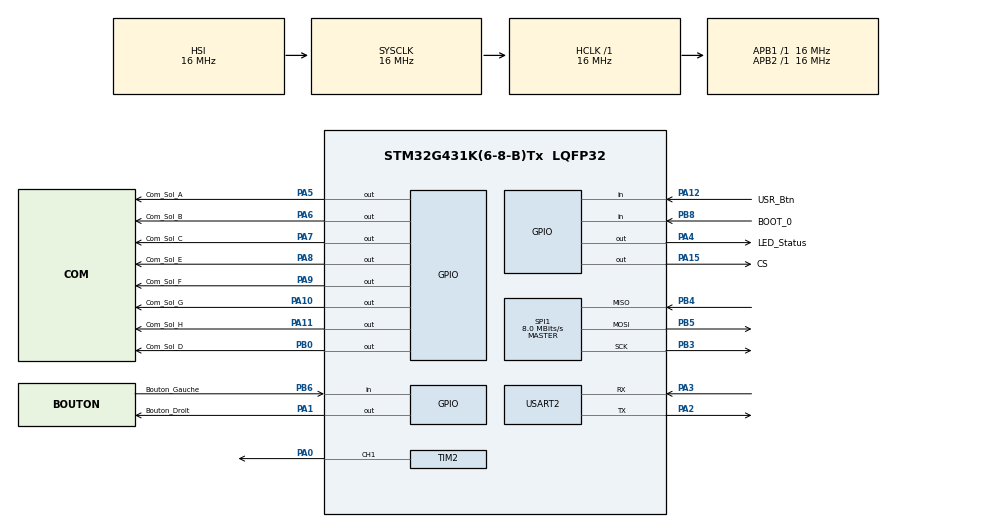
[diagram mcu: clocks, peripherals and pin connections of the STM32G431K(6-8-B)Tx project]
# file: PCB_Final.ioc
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Dma.Request0=TIM2_CH1
Dma.TIM2_CH1.0.Direction=DMA_MEMORY_TO_PERIPH
Dma.TIM2_CH1.0.EventEnable=DISABLE
Dma.TIM2_CH1.0.Instance=DMA1_Channel1
Dma.TIM2_CH1.0.MemDataAlignment=DMA_MDATAALIGN_WORD
Dma.TIM2_CH1.0.MemInc=DMA_MINC_ENABLE
Dma.TIM2_CH1.0.Mode=DMA_CIRCULAR
Dma.TIM2_CH1.0.PeriphDataAlignment=DMA_PDATAALIGN_WORD
Dma.TIM2_CH1.0.PeriphInc=DMA_PINC_DISABLE
Dma.TIM2_CH1.0.Polarity=HAL_DMAMUX_REQ_GEN_RISING
Dma.TIM2_CH1.0.Priority=DMA_PRIORITY_LOW
Dma.TIM2_CH1.0.RequestNumber=1
Dma.TIM2_CH1.0.SignalID=NONE
Dma.TIM2_CH1.0.SyncEnable=DISABLE
Dma.TIM2_CH1.0.SyncPolarity=HAL_DMAMUX_SYNC_NO_EVENT
Dma.TIM2_CH1.0.SyncRequestNumber=1
Dma.TIM2_CH1.0.SyncSignalID=NONE
Mcu.Family=STM32G4
Mcu.Name=STM32G431K(6-8-B)Tx
Mcu.Package=LQFP32
NVIC.DMA1_Channel1_IRQn=true\:0\:0\:false\:false\:true\:false\:true\:true
NVIC.PriorityGroup=NVIC_PRIORITYGROUP_4
NVIC.TIM2_IRQn=true\:0\:0\:false\:false\:true\:true\:true\:true
PA0.Signal=S_TIM2_CH1
PA1.GPIO_Label=Bouton_Droit
PA1.Signal=GPIO_Output
PA10.GPIO_Label=Com_Sol_G
PA10.Signal=GPIO_Output
PA11.GPIO_Label=Com_Sol_H
PA11.Signal=GPIO_Output
PA12.GPIO_Label=USR_Btn
PA12.Signal=GPIO_Input
PA13.Signal=SYS_JTMS-SWDIO
PA14.Signal=SYS_JTCK-SWCLK
PA15.GPIO_Label=CS
PA15.Signal=GPIO_Output
PA2.Mode=Asynchronous
PA2.Signal=USART2_TX
PA3.Mode=Asynchronous
PA3.Signal=USART2_RX
PA4.GPIO_Label=LED_Status
PA4.Signal=GPIO_Output
PA5.GPIO_Label=Com_Sol_A
PA5.Signal=GPIO_Output
PA6.GPIO_Label=Com_Sol_B
PA6.Signal=GPIO_Output
PA7.GPIO_Label=Com_Sol_C
PA7.Signal=GPIO_Output
PA8.GPIO_Label=Com_Sol_E
PA8.Signal=GPIO_Output
PA9.GPIO_Label=Com_Sol_F
PA9.Signal=GPIO_Output
PB0.GPIO_Label=Com_Sol_D
PB0.Signal=GPIO_Output
PB3.Mode=Full_Duplex_Master
PB3.Signal=SPI1_SCK
PB4.Mode=Full_Duplex_Master
PB4.Signal=SPI1_MISO
PB5.Mode=Full_Duplex_Master
PB5.Signal=SPI1_MOSI
PB6.GPIO_Label=Bouton_Gauche
PB6.Signal=GPIO_Input
PB8-BOOT0.GPIO_Label=BOOT_0
PB8-BOOT0.Signal=GPIO_Input
ProjectManager.HeapSize=0x200
ProjectManager.StackSize=0x400
ProjectManager.TargetToolchain=STM32CubeIDE
RCC.AHBFreq_Value=16000000
RCC.APB1Freq_Value=16000000
RCC.APB1TimFreq_Value=16000000
RCC.APB2Freq_Value=16000000
RCC.APB2TimFreq_Value=16000000
RCC.CortexFreq_Value=16000000
RCC.EXTERNAL_CLOCK_VALUE=12288000
RCC.HCLKFreq_Value=16000000
RCC.HSE_VALUE=8000000
RCC.HSI48_VALUE=48000000
RCC.HSI_VALUE=16000000
RCC.LSE_VALUE=32768
RCC.SYSCLKFreq_VALUE=16000000
RCC.USBFreq_Value=64000000
RCC.VCOOutputFreq_Value=128000000
SH.S_TIM2_CH1.0=TIM2_CH1,PWM Generation1 CH1
SPI1.CalculateBaudRate=8.0 MBits/s
SPI1.Direction=SPI_DIRECTION_2LINES
SPI1.Mode=SPI_MODE_MASTER
SPI1.VirtualType=VM_MASTER
TIM2.Channel-PWM\ Generation1\ CH1=TIM_CHANNEL_1
USART2.VirtualMode-Asynchronous=VM_ASYNC
VP_SYS_VS_DBSignals.Mode=DisableDeadBatterySignals
board=custom

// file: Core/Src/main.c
/* USER CODE BEGIN Header */
/**
  ******************************************************************************
  * @file           : main.c
  * @brief          : Main program body
  ******************************************************************************
  * @attention
  *
  * Copyright (c) 2026 STMicroelectronics.
  * All rights reserved.
  *
  * This software is licensed under terms that can be found in the LICENSE file
  * in the root directory of this software component.
  * If no LICENSE file comes with this software, it is provided AS-IS.
  *
  ******************************************************************************
  */
/* USER CODE END Header */
#include "main.h"

SPI_HandleTypeDef hspi1;

TIM_HandleTypeDef htim2;
DMA_HandleTypeDef hdma_tim2_ch1;

UART_HandleTypeDef huart2;

void SystemClock_Config(void);
static void MX_GPIO_Init(void);
static void MX_DMA_Init(void);
static void MX_USART2_UART_Init(void);
static void MX_TIM2_Init(void);
static void MX_SPI1_Init(void);

int main(void)
{

  /* MCU Configuration--------------------------------------------------------*/

  /* Reset of all peripherals, Initializes the Flash interface and the Systick. */
  HAL_Init();

  /* Configure the system clock */
  SystemClock_Config();

  /* Initialize all configured peripherals */
  MX_GPIO_Init();
  MX_DMA_Init();
  MX_USART2_UART_Init();
  MX_TIM2_Init();
  MX_SPI1_Init();
  /* USER CODE BEGIN 2 */
uint32_t tableau[24] = {0};	// timings 1 et 0

HAL_TIM_PWM_Start_DMA(&htim2, TIM_CHANNEL_1, tableau, 24);
  /* USER CODE END 2 */

  /* Infinite loop */
  while (1)
  {

  }
}

void SystemClock_Config(void)
{
  RCC_OscInitTypeDef RCC_OscInitStruct = {0};
  RCC_ClkInitTypeDef RCC_ClkInitStruct = {0};

  /** Configure the main internal regulator output voltage
  */
  HAL_PWREx_ControlVoltageScaling(PWR_REGULATOR_VOLTAGE_SCALE1);

  /** Initializes the RCC Oscillators according to the specified parameters
  * in the RCC_OscInitTypeDef structure.
  */
  RCC_OscInitStruct.OscillatorType = RCC_OSCILLATORTYPE_HSI;
  RCC_OscInitStruct.HSIState = RCC_HSI_ON;
  RCC_OscInitStruct.HSICalibrationValue = RCC_HSICALIBRATION_DEFAULT;
  RCC_OscInitStruct.PLL.PLLState = RCC_PLL_NONE;
  if (HAL_RCC_OscConfig(&RCC_OscInitStruct) != HAL_OK)
  {
    Error_Handler();
  }

  /** Initializes the CPU, AHB and APB buses clocks
  */
  RCC_ClkInitStruct.ClockType = RCC_CLOCKTYPE_HCLK|RCC_CLOCKTYPE_SYSCLK
                              |RCC_CLOCKTYPE_PCLK1|RCC_CLOCKTYPE_PCLK2;
  RCC_ClkInitStruct.SYSCLKSource = RCC_SYSCLKSOURCE_HSI;
  RCC_ClkInitStruct.AHBCLKDivider = RCC_SYSCLK_DIV1;
  RCC_ClkInitStruct.APB1CLKDivider = RCC_HCLK_DIV1;
  RCC_ClkInitStruct.APB2CLKDivider = RCC_HCLK_DIV1;

  if (HAL_RCC_ClockConfig(&RCC_ClkInitStruct, FLASH_LATENCY_0) != HAL_OK)
  {
    Error_Handler();
  }
}

static void MX_SPI1_Init(void)
{

  /* SPI1 parameter configuration*/
  hspi1.Instance = SPI1;
  hspi1.Init.Mode = SPI_MODE_MASTER;
  hspi1.Init.Direction = SPI_DIRECTION_2LINES;
  hspi1.Init.DataSize = SPI_DATASIZE_4BIT;
  hspi1.Init.CLKPolarity = SPI_POLARITY_LOW;
  hspi1.Init.CLKPhase = SPI_PHASE_1EDGE;
  hspi1.Init.NSS = SPI_NSS_SOFT;
  hspi1.Init.BaudRatePrescaler = SPI_BAUDRATEPRESCALER_2;
  hspi1.Init.FirstBit = SPI_FIRSTBIT_MSB;
  hspi1.Init.TIMode = SPI_TIMODE_DISABLE;
  hspi1.Init.CRCCalculation = SPI_CRCCALCULATION_DISABLE;
  hspi1.Init.CRCPolynomial = 7;
  hspi1.Init.CRCLength = SPI_CRC_LENGTH_DATASIZE;
  hspi1.Init.NSSPMode = SPI_NSS_PULSE_ENABLE;
  if (HAL_SPI_Init(&hspi1) != HAL_OK)
  {
    Error_Handler();
  }

}

static void MX_TIM2_Init(void)
{

  TIM_MasterConfigTypeDef sMasterConfig = {0};
  TIM_OC_InitTypeDef sConfigOC = {0};

  htim2.Instance = TIM2;
  htim2.Init.Prescaler = 0;
  htim2.Init.CounterMode = TIM_COUNTERMODE_UP;
  htim2.Init.Period = 4294967295;
  htim2.Init.ClockDivision = TIM_CLOCKDIVISION_DIV1;
  htim2.Init.AutoReloadPreload = TIM_AUTORELOAD_PRELOAD_DISABLE;
  if (HAL_TIM_PWM_Init(&htim2) != HAL_OK)
  {
    Error_Handler();
  }
  sMasterConfig.MasterOutputTrigger = TIM_TRGO_RESET;
  sMasterConfig.MasterSlaveMode = TIM_MASTERSLAVEMODE_DISABLE;
  if (HAL_TIMEx_MasterConfigSynchronization(&htim2, &sMasterConfig) != HAL_OK)
  {
    Error_Handler();
  }
  sConfigOC.OCMode = TIM_OCMODE_PWM1;
  sConfigOC.Pulse = 0;
  sConfigOC.OCPolarity = TIM_OCPOLARITY_HIGH;
  sConfigOC.OCFastMode = TIM_OCFAST_DISABLE;
  if (HAL_TIM_PWM_ConfigChannel(&htim2, &sConfigOC, TIM_CHANNEL_1) != HAL_OK)
  {
    Error_Handler();
  }
  HAL_TIM_MspPostInit(&htim2);

}

static void MX_USART2_UART_Init(void)
{

  huart2.Instance = USART2;
  huart2.Init.BaudRate = 115200;
  huart2.Init.WordLength = UART_WORDLENGTH_8B;
  huart2.Init.StopBits = UART_STOPBITS_1;
  huart2.Init.Parity = UART_PARITY_NONE;
  huart2.Init.Mode = UART_MODE_TX_RX;
  huart2.Init.HwFlowCtl = UART_HWCONTROL_NONE;
  huart2.Init.OverSampling = UART_OVERSAMPLING_16;
  huart2.Init.OneBitSampling = UART_ONE_BIT_SAMPLE_DISABLE;
  huart2.Init.ClockPrescaler = UART_PRESCALER_DIV1;
  huart2.AdvancedInit.AdvFeatureInit = UART_ADVFEATURE_NO_INIT;
  if (HAL_UART_Init(&huart2) != HAL_OK)
  {
    Error_Handler();
  }
  if (HAL_UARTEx_SetTxFifoThreshold(&huart2, UART_TXFIFO_THRESHOLD_1_8) != HAL_OK)
  {
    Error_Handler();
  }
  if (HAL_UARTEx_SetRxFifoThreshold(&huart2, UART_RXFIFO_THRESHOLD_1_8) != HAL_OK)
  {
    Error_Handler();
  }
  if (HAL_UARTEx_DisableFifoMode(&huart2) != HAL_OK)
  {
    Error_Handler();
  }

}

static void MX_DMA_Init(void)
{

  /* DMA controller clock enable */
  __HAL_RCC_DMAMUX1_CLK_ENABLE();
  __HAL_RCC_DMA1_CLK_ENABLE();

  /* DMA interrupt init */
  /* DMA1_Channel1_IRQn interrupt configuration */
  HAL_NVIC_SetPriority(DMA1_Channel1_IRQn, 0, 0);
  HAL_NVIC_EnableIRQ(DMA1_Channel1_IRQn);

}

static void MX_GPIO_Init(void)
{
  GPIO_InitTypeDef GPIO_InitStruct = {0};

  /* GPIO Ports Clock Enable */
  __HAL_RCC_GPIOA_CLK_ENABLE();
  __HAL_RCC_GPIOB_CLK_ENABLE();

  /*Configure GPIO pin Output Level */
  HAL_GPIO_WritePin(GPIOA, Bouton_Droit_Pin|LED_Status_Pin|Com_Sol_A_Pin|Com_Sol_B_Pin
                          |Com_Sol_C_Pin|Com_Sol_E_Pin|Com_Sol_F_Pin|Com_Sol_G_Pin
                          |Com_Sol_H_Pin|CS_Pin, GPIO_PIN_RESET);

  /*Configure GPIO pin Output Level */
  HAL_GPIO_WritePin(Com_Sol_D_GPIO_Port, Com_Sol_D_Pin, GPIO_PIN_RESET);

  /*Configure GPIO pins : Bouton_Droit_Pin LED_Status_Pin Com_Sol_A_Pin Com_Sol_B_Pin
                           Com_Sol_C_Pin Com_Sol_E_Pin Com_Sol_F_Pin Com_Sol_G_Pin
                           Com_Sol_H_Pin CS_Pin */
  GPIO_InitStruct.Pin = Bouton_Droit_Pin|LED_Status_Pin|Com_Sol_A_Pin|Com_Sol_B_Pin
                          |Com_Sol_C_Pin|Com_Sol_E_Pin|Com_Sol_F_Pin|Com_Sol_G_Pin
                          |Com_Sol_H_Pin|CS_Pin;
  GPIO_InitStruct.Mode = GPIO_MODE_OUTPUT_PP;
  GPIO_InitStruct.Pull = GPIO_NOPULL;
  GPIO_InitStruct.Speed = GPIO_SPEED_FREQ_LOW;
  HAL_GPIO_Init(GPIOA, &GPIO_InitStruct);

  /*Configure GPIO pin : Com_Sol_D_Pin */
  GPIO_InitStruct.Pin = Com_Sol_D_Pin;
  GPIO_InitStruct.Mode = GPIO_MODE_OUTPUT_PP;
  GPIO_InitStruct.Pull = GPIO_NOPULL;
  GPIO_InitStruct.Speed = GPIO_SPEED_FREQ_LOW;
  HAL_GPIO_Init(Com_Sol_D_GPIO_Port, &GPIO_InitStruct);

  /*Configure GPIO pin : USR_Btn_Pin */
  GPIO_InitStruct.Pin = USR_Btn_Pin;
  GPIO_InitStruct.Mode = GPIO_MODE_INPUT;
  GPIO_InitStruct.Pull = GPIO_NOPULL;
  HAL_GPIO_Init(USR_Btn_GPIO_Port, &GPIO_InitStruct);

  /*Configure GPIO pins : Bouton_Gauche_Pin BOOT_0_Pin */
  GPIO_InitStruct.Pin = Bouton_Gauche_Pin|BOOT_0_Pin;
  GPIO_InitStruct.Mode = GPIO_MODE_INPUT;
  GPIO_InitStruct.Pull = GPIO_NOPULL;
  HAL_GPIO_Init(GPIOB, &GPIO_InitStruct);

}

void Error_Handler(void)
{
  __disable_irq();
  while (1)
  {
  }
}
